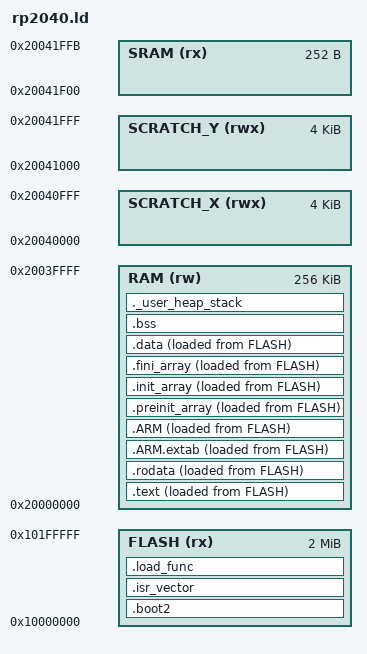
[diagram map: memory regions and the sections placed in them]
/* Entry Point */
ENTRY(Reset_Handler)

/* Highest address of the user mode stack */
_estack = ORIGIN(RAM) + LENGTH(RAM); /* end of "RAM" Ram type memory */

_Min_Heap_Size = 0x200; /* required amount of heap */
_Min_Stack_Size = 0x400; /* required amount of stack */

/* Memories definition */
MEMORY
{
  SRAM(rx)       : ORIGIN = 0x20041f00,    LENGTH = 252
  RAM       (rw) : ORIGIN = 0x20000000,    LENGTH = 256k
  SCRATCH_X(rwx) : ORIGIN = 0x20040000,    LENGTH = 4k
  SCRATCH_Y(rwx) : ORIGIN = 0x20041000,    LENGTH = 4k
  FLASH     (rx) : ORIGIN = 0x10000000,    LENGTH = 2048k
}

/* Sections */
SECTIONS
{
  .boot2 : 
  {
        __boot2_start__ = .;
        KEEP (*(.boot2))
        __boot2_end__ = .;
  } >FLASH

  ASSERT(__boot2_end__ - __boot2_start__ == 256,
        "ERROR: Pico second stage bootloader must be 256 bytes in size")

  /* The startup code into "FLASH" Rom type memory */
  .isr_vector :
  {
    . = ALIGN(4);
    KEEP(*(.isr_vector)) /* Startup code */
    . = ALIGN(4);
  } >FLASH

  .load_func :
  {
    . = ALIGN(4);
    *(.load_func)
    *(.load_func*)
    . = ALIGN(4);
  } >FLASH

  /* The program code and other data into "FLASH" Rom type memory */
  _siram_app  = LOADADDR(.text);
  .text :
  {
    . = ALIGN(4);
    _sram_app = .;     /* Define start of RAM application */
    *(.text)           /* .text sections (code) */   
    *(.text*)          /* .text* sections (code) */
    *(.glue_7)         /* glue arm to thumb code */
    *(.glue_7t)        /* glue thumb to arm code */
    *(.eh_frame)

    KEEP (*(.init))
    KEEP (*(.fini))

    . = ALIGN(4);
  } >RAM AT >FLASH

  /* Constant data into "FLASH" Rom type memory */
  .rodata :
  {
    . = ALIGN(4);
    *(.rodata)         /* .rodata sections (constants, strings, etc.) */
    *(.rodata*)        /* .rodata* sections (constants, strings, etc.) */
    . = ALIGN(4);
  } >RAM AT >FLASH

  .ARM.extab   : {
    . = ALIGN(4);
    *(.ARM.extab* .gnu.linkonce.armextab.*)
    . = ALIGN(4);
  } >RAM AT >FLASH

  .ARM : {
    . = ALIGN(4);
    __exidx_start = .;
    *(.ARM.exidx*)
    __exidx_end = .;
    . = ALIGN(4);
  } >RAM AT >FLASH

  .preinit_array     :
  {
    . = ALIGN(4);
    PROVIDE_HIDDEN (__preinit_array_start = .);
    KEEP (*(.preinit_array*))
    PROVIDE_HIDDEN (__preinit_array_end = .);
    . = ALIGN(4);
  } >RAM AT >FLASH

  .init_array :
  {
    . = ALIGN(4);
    PROVIDE_HIDDEN (__init_array_start = .);
    KEEP (*(SORT(.init_array.*)))
    KEEP (*(.init_array*))
    PROVIDE_HIDDEN (__init_array_end = .);
    . = ALIGN(4);
  } >RAM AT >FLASH

  .fini_array :
  {
    . = ALIGN(4);
    PROVIDE_HIDDEN (__fini_array_start = .);
    KEEP (*(SORT(.fini_array.*)))
    KEEP (*(.fini_array*))
    PROVIDE_HIDDEN (__fini_array_end = .);
    . = ALIGN(4);
    _eram_app = .;     /* Define end of RAM application */
  } >RAM AT >FLASH

  /* Used by the startup to initialize data */
  _sidata = LOADADDR(.data);

  /* Initialized data sections into "RAM" Ram type memory */
  .data :
  {
    . = ALIGN(4);
    _sdata = .;        /* create a global symbol at data start */
    *(.data)           /* .data sections */
    *(.data*)          /* .data* sections */
    *(.RamFunc)        /* .RamFunc sections */
    *(.RamFunc*)       /* .RamFunc* sections */

    . = ALIGN(4);
    _edata = .;        /* define a global symbol at data end */

  } >RAM AT> FLASH

  /* Uninitialized data section into "RAM" Ram type memory */
  . = ALIGN(4);
  .bss :
  {
    /* This is used by the startup in order to initialize the .bss section */
    _sbss = .;         /* define a global symbol at bss start */
    __bss_start__ = _sbss;
    *(.bss)
    *(.bss*)
    *(COMMON)

    . = ALIGN(4);
    _ebss = .;         /* define a global symbol at bss end */
    __bss_end__ = _ebss;
  } >RAM

  /* User_heap_stack section, used to check that there is enough "RAM" Ram  type memory left */
  ._user_heap_stack :
  {
    . = ALIGN(8);
    PROVIDE ( end = . );
    PROVIDE ( _end = . );
    . = . + _Min_Heap_Size;
    . = . + _Min_Stack_Size;
    . = ALIGN(8);
  } >RAM

  /* Remove information from the compiler libraries */
  /DISCARD/ :
  {
    libc.a ( * )
    libm.a ( * )
    libgcc.a ( * )
  }

  .ARM.attributes 0 : { *(.ARM.attributes) }
}
